# SAMA7D65D2GN8 register map
Vendor: Microchip Technology; Series: SAMA7D6; File version: 0
Registers are 32-bit, read-write, reset 0x0 unless marked. A register's access mark holds for its fields unless they carry their own. Offsets are from the block's base; [hi:lo] are bit positions; lines under a group give offsets from that group; {n}, {i} and the like mark numbered series; 'fields as' and 'values as' point back to an identical list.

## MATRIX — AHB Bus Matrix (MATRIX2)
Base 0xE0804000
{0x0+4i} MCFG[{i}] (i=0..13) reset 0x4 — Host Configuration Register x
  [2:0] ULBT — Undefined Length Burst Type
    0=UNLIMITED (Unlimited Length Burst-No predicted end of burst is generated, therefore INCR bursts coming from this host can only be broken if the Client Slot Cycle Limit is reached. If the Slot Cycle Limit is not reached, the burst is normally completed by the host, at the latest, on the next system bus 1 Kbyte address boundary, allowing up to 256-beat word bursts or 128-beat double-word bursts. This value should not be used in the very particular case of a host capable of performing back-to-back undefined length bursts on a single client, since this could indefinitely freeze the client arbitration and thus prevent another host from accessing this client.); 1=SINGLE (Single Access-The undefined length burst is treated as a succession of single accesses, allowing re-arbitration at each beat of the INCR burst or bursts sequence.); 2=4_BEAT (4-beat Burst-The undefined length burst or bursts sequence is split into 4-beat bursts or less, allowing re-arbitration every 4 beats.); 3=8_BEAT (8-beat Burst-The undefined length burst or bursts sequence is split into 8-beat bursts or less, allowing re-arbitration every 8 beats.); 4=16_BEAT (16-beat Burst-The undefined length burst or bursts sequence is split into 16-beat bursts or less, allowing re-arbitration every 16 beats.); 5=32_BEAT (32-beat Burst-The undefined length burst or bursts sequence is split into 32-beat bursts or less, allowing re-arbitration every 32 beats.); 6=64_BEAT (64-beat Burst-The undefined length burst or bursts sequence is split into 64-beat bursts or less, allowing re-arbitration every 64 beats.); 7=128_BEAT (128-beat Burst-The undefined length burst or bursts sequence is split into 128-beat bursts or less, allowing re-arbitration every 128 beats. Unless duly needed, the ULBT should be left at its default 0 value for power saving.)
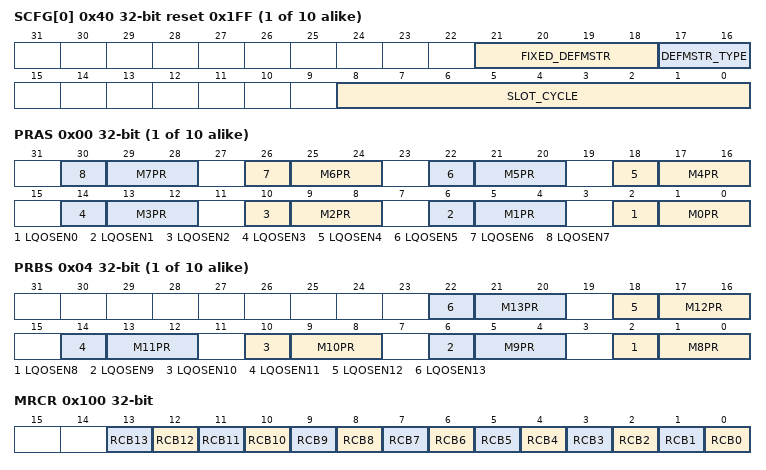
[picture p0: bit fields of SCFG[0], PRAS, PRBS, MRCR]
{0x40+4i} SCFG[{i}] (i=0..9) reset 0x1FF — Client Configuration Register x
  [21:18] FIXED_DEFMSTR — Fixed Default Host
  [17:16] DEFMSTR_TYPE — Default Host Type
    0=NONE (No Default Host-At the end of the current client access, if no other host request is pending, the client is disconnected from all hosts. This results in a one clock cycle latency for the first access of a burst transfer or for a single access.); 1=LAST (Last Default Host-At the end of the current client access, if no other host request is pending, the client stays connected to the last host having accessed it. This results in not having one clock cycle latency when the last host tries to access the client again.); 2=FIXED (Fixed Default Host-At the end of the current client access, if no other host request is pending, the client connects to the fixed host the number that has been written in the FIXED_DEFMSTR field. This results in not having one clock cycle latency when the fixed host tries to access the client again.)
  [8:0] SLOT_CYCLE — Maximum Bus Grant Duration for Hosts
{0x80+8i} MATRIX_PR[{i}] (i=0..9) group
  0x00 PRAS — Priority Register A for Client x
    [4n+2] LQOSEN{n} (n=0..7) — Latency Quality of Service Enable for Host {n}
      0=Disables propagation of Latency Quality of Service from the Host x to the Client and apply MxPR priority for all access from Host x to the Client; 1=Enables the propagation of Latency Quality of Service from the Host x to the Client if supported by the Host x
    [4n+1:4n] M{n}PR (n=0..7) — Host {n} Priority
  0x04 PRBS — Priority Register B for Client x
    [4n-30] LQOSEN{n} (n=8..13) — Latency Quality of Service Enable for Host {n}
      values as MATRIX_PR[0].PRAS.LQOSEN0
    [4n-31:4n-32] M{n}PR (n=8..13) — Host {n} Priority
0x100 MRCR — Host Remap Control Register
  [all] fields
    0=Disables remapped address decoding for the selected Host; 1=Enables remapped address decoding for the selected Host
  [n] RCB{n} (n=0..13) — Remap Command Bit for Host {n}
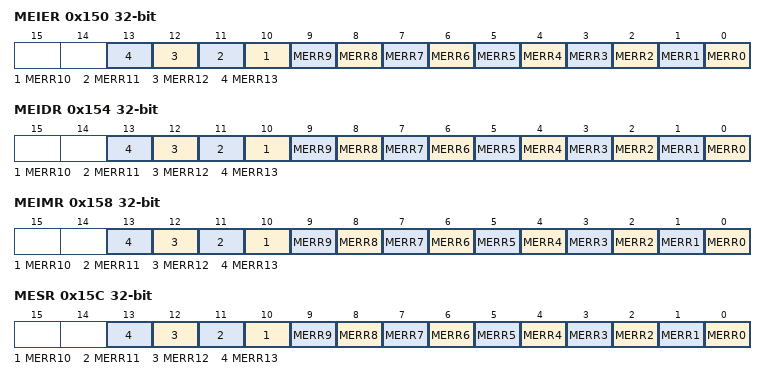
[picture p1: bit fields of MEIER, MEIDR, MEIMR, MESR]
0x150 MEIER wo — Host Error Interrupt Enable Register
  [all] fields
    0=No effect; 1=Enables Host x Access Error interrupt source
  [n] MERR{n} (n=0..13) — Host {n} Access Error
0x154 MEIDR wo — Host Error Interrupt Disable Register
  [all] fields
    0=No effect; 1=Disables Host x Access Error interrupt source
  [n] MERR{n} (n=0..13) — Host {n} Access Error
0x158 MEIMR ro — Host Error Interrupt Mask Register
  [all] fields
    0=Host x Access Error does not trigger any interrupt; 1=Host x Access Error triggers the MATRIX interrupt line
  [n] MERR{n} (n=0..13) — Host {n} Access Error
0x15C MESR ro — Host Error Status Register
  [all] fields
    0=No Host Access Error has occurred since the last read of the MATRIX_MESR; 1=At least one Host Access Error has occurred since the last read of the MATRIX_MESR
  [n] MERR{n} (n=0..13) — Host {n} Access Error
{0x160+4i} MEAR[{i}] (i=0..13) ro — Host x Error Address Register
  [31:0] ERRADD — Host Error Address
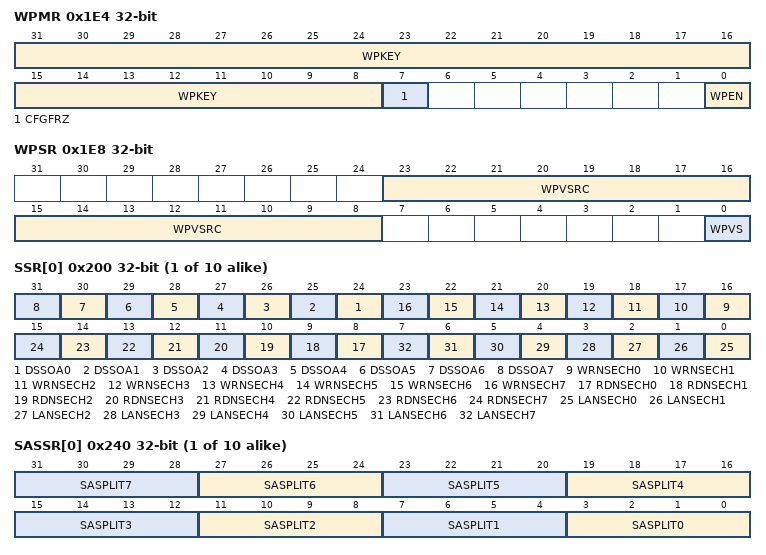
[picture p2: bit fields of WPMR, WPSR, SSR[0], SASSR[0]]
0x1E4 WPMR — Write Protect Mode Register
  [31:8] WPKEY — Write Protection Key
    0x4D4154=PASSWD (Writing any other value in this field aborts the write operation of the WPEN and CFGFRZ bits. Always reads as 0.)
  [7] CFGFRZ — Configuration Freeze
    0=The MATRIX configuration is not frozen; 1=Freezes the MATRIX configuration until hardware reset. The registers that can be protected by the WPEN bit and the Write Protection Mode Register are no longer modifiable.
  [0] WPEN — Write Protection Enable
    0=Disables the write protection if WPKEY corresponds to 0x4D4154 ('MAT' in ASCII); 1=Enables the write protection if WPKEY corresponds to 0x4D4154 ('MAT' in ASCII)
0x1E8 WPSR ro — Write Protect Status Register
  [23:8] WPVSRC — Write Protection Violation Source
  [0] WPVS — Write Protection Violation Status
    0=No write protection violation has occurred since the last write of the MATRIX_WPMR; 1=A write protection violation has occurred since the last write of the MATRIX_WPMR. If this violation is an unauthorized attempt to write a protected register, the associated violation is reported into field WPVSRC.
{0x200+4i} SSR[{i}] (i=0..9) — Security Client x Register
  [n+24] DSSOA{n} (n=0..7) — Downward Security Split Offset Address for HSELx Security Region
    0=For the HSELx client security region, the security area split MATRIX_SASSR / SASPLITx defines the size of the client security area starting from the base address of the client security region and up; 1=For the HSELx client security region, the security area split MATRIX_SASSR / SASPLITx defines the size of the client security area starting from the end address of the client security region and down
  [n+16] WRNSECH{n} (n=0..7) — Write Not Secured for HSELx Security Region
    0=The HSELx client security region is split into one Write Secured and one Write Not Secured area, according to LANSECHx and MATRIX_SASSR / SASPLITx. That is, the so defined securable high or low area is Secured for Write access.; 1=The HSELx client security region is Not Secured for Write access
  [n+8] RDNSECH{n} (n=0..7) — Read Not Secured for HSELx Security Region
    0=The HSELx client security region is split into one Read Secured and one Read Not Secured area, according to LANSECHx and MATRIX_SASSR / SASPLITx. That is, the so defined securable high or low area is Secured for Read access.; 1=The HSELx client security region is Not Secured for Read access
  [n] LANSECH{n} (n=0..7) — Low Area Not Secured in HSELx Security Region
    0=The security of the HSELx client area laying below the corresponding MATRIX_SASSR / SASPLITx boundary is configured according to RDNSECHx and WRNSECHx. The whole remaining HSELx upper address space is configured as Not Secured access.; 1=The HSELx client address area laying below the corresponding MATRIX_SASSR / SASPLITx boundary is configured as Not Secured access, and the whole remaining upper address space according to RDNSECHx and WRNSECHx
{0x240+4i} SASSR[{i}] (i=0..9) — Security Areas Split Client x Register
  [4n+3:4n] SASPLIT{n} (n=0..7) — Security Areas Split for HSELx Security Region
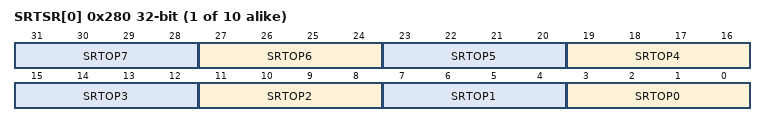
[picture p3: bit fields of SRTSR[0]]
{0x280+4i} SRTSR[{i}] (i=0..9) — Security Region Top Client x Register
  [4n+3:4n] SRTOP{n} (n=0..7) — HSELx Security Region Top
